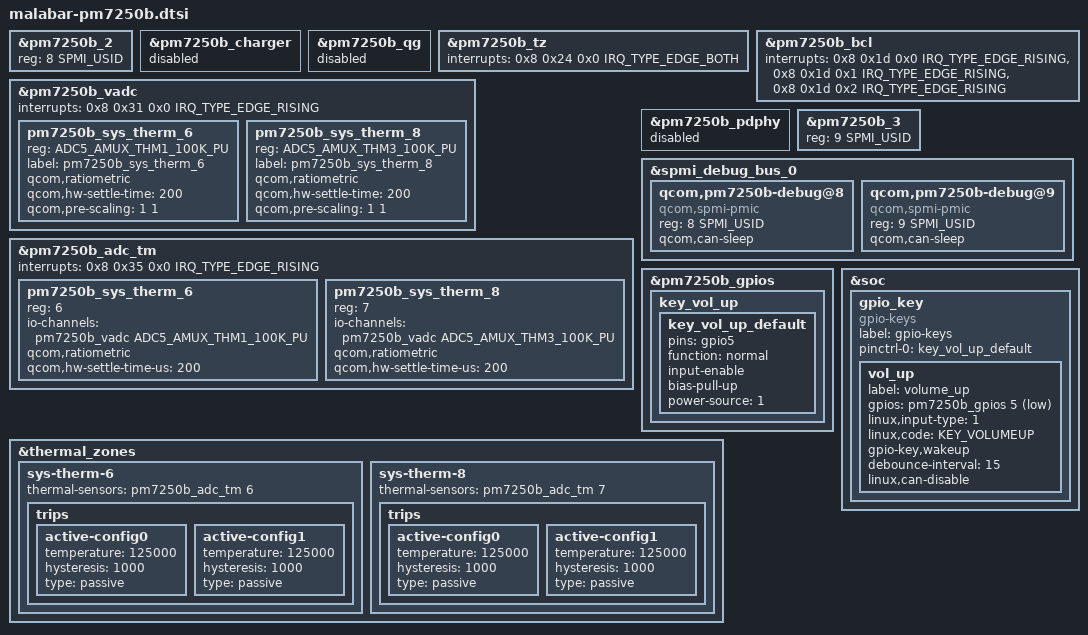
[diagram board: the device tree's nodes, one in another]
// SPDX-License-Identifier: BSD-3-Clause
/*
 * Copyright (c) Qualcomm Technologies, Inc. and/or its subsidiaries.
 */

#include "pm7250b.dtsi"

&pm7250b_2 {
	reg = <8 SPMI_USID>;
};

&pm7250b_charger {
	status = "disabled";
};

&pm7250b_qg {
	status = "disabled";
};

&pm7250b_tz {
	interrupts = <0x8 0x24 0x0 IRQ_TYPE_EDGE_BOTH>;
};

&pm7250b_vadc {
	interrupts = <0x8 0x31 0x0 IRQ_TYPE_EDGE_RISING>;

	pm7250b_sys_therm_6 {
		reg = <ADC5_AMUX_THM1_100K_PU>;
		label = "pm7250b_sys_therm_6";
		qcom,ratiometric;
		qcom,hw-settle-time = <200>;
		qcom,pre-scaling = <1 1>;
	};

	pm7250b_sys_therm_8 {
		reg = <ADC5_AMUX_THM3_100K_PU>;
		label = "pm7250b_sys_therm_8";
		qcom,ratiometric;
		qcom,hw-settle-time = <200>;
		qcom,pre-scaling = <1 1>;
	};
};

&pm7250b_adc_tm {
	interrupts = <0x8 0x35 0x0 IRQ_TYPE_EDGE_RISING>;

	pm7250b_sys_therm_6 {
		reg = <6>;
		io-channels = <&pm7250b_vadc ADC5_AMUX_THM1_100K_PU>;
		qcom,ratiometric;
		qcom,hw-settle-time-us = <200>;
	};

	pm7250b_sys_therm_8 {
		reg = <7>;
		io-channels = <&pm7250b_vadc ADC5_AMUX_THM3_100K_PU>;
		qcom,ratiometric;
		qcom,hw-settle-time-us = <200>;
	};
};

&pm7250b_bcl {
	interrupts = <0x8 0x1d 0x0 IRQ_TYPE_EDGE_RISING>,
		     <0x8 0x1d 0x1 IRQ_TYPE_EDGE_RISING>,
		     <0x8 0x1d 0x2 IRQ_TYPE_EDGE_RISING>;
};

&pm7250b_pdphy {
	status = "disabled";
};

&pm7250b_3 {
	reg = <9 SPMI_USID>;
};

&spmi_debug_bus_0 {
	qcom,pm7250b-debug@8 {
		compatible = "qcom,spmi-pmic";
		reg = <8 SPMI_USID>;
		#address-cells = <2>;
		#size-cells = <0>;
		qcom,can-sleep;
	};

	qcom,pm7250b-debug@9 {
		compatible = "qcom,spmi-pmic";
		reg = <9 SPMI_USID>;
		#address-cells = <2>;
		#size-cells = <0>;
		qcom,can-sleep;
	};
};

&pm7250b_gpios {
	key_vol_up {
		key_vol_up_default: key_vol_up_default {
			pins = "gpio5";
			function = "normal";
			input-enable;
			bias-pull-up;
			power-source = <1>;
		};
	};
};

&soc {
	gpio_key {
		compatible = "gpio-keys";
		label = "gpio-keys";
		pinctrl-names = "default";
		pinctrl-0 = <&key_vol_up_default>;
		vol_up {
			label = "volume_up";
			gpios = <&pm7250b_gpios 5 GPIO_ACTIVE_LOW>;
			linux,input-type = <1>;
			linux,code = <KEY_VOLUMEUP>;
			gpio-key,wakeup;
			debounce-interval = <15>;
			linux,can-disable;
		};
	};
};

&thermal_zones {
	sys-therm-6 {
		thermal-sensors = <&pm7250b_adc_tm 6>;

		trips {
			active-config0 {
				temperature = <125000>;
				hysteresis = <1000>;
				type = "passive";
			};

			active-config1 {
				temperature = <125000>;
				hysteresis = <1000>;
				type = "passive";
			};
		};
	};

	sys-therm-8 {
		thermal-sensors = <&pm7250b_adc_tm 7>;

		trips {
			active-config0 {
				temperature = <125000>;
				hysteresis = <1000>;
				type = "passive";
			};

			active-config1 {
				temperature = <125000>;
				hysteresis = <1000>;
				type = "passive";
			};
		};
	};
};
